# ATSAMRH707F18A register map
Vendor: Microchip Technology; Series: SAMRH707; File version: 0
CPU: CM7 r1p1, little endian, MPU, FPU, double-precision FPU, I-cache, D-cache, ITCM, DTCM, 3 interrupt priority bits, 69 interrupts
Registers are 32-bit, read-write, reset 0x0 unless marked. A register's access mark holds for its fields unless they carry their own. Offsets are from the block's base; [hi:lo] are bit positions; {n}, {i} and the like mark numbered series; 'fields as' and 'values as' point back to an identical list.

## PMC — Power Management Controller
Base 0x4000C000
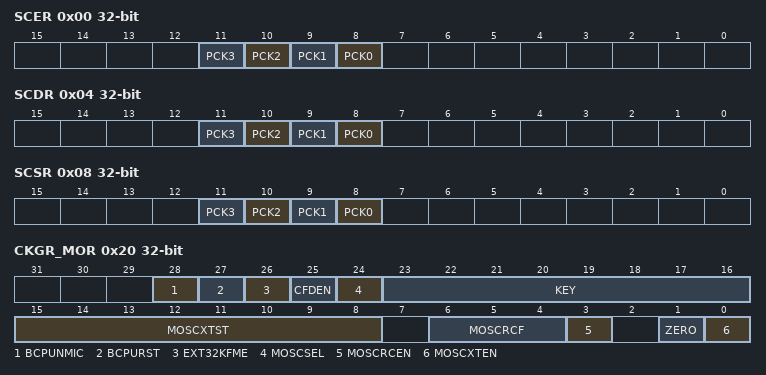
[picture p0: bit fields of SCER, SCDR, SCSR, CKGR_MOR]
0x00 SCER wo — System Clock Enable Register
  [n+8] PCK{n} (n=0..3) — Programmable Clock {n} Output Enable
0x04 SCDR wo — System Clock Disable Register
  [n+8] PCK{n} (n=0..3) — Programmable Clock {n} Output Disable
0x08 SCSR ro — System Clock Status Register
  [n+8] PCK{n} (n=0..3) — Programmable Clock {n} Output Status
0x20 CKGR_MOR — Main Oscillator Register
  [28] BCPUNMIC — Bad CPU Clock Interrupt to NMIC Enable
  [27] BCPURST — Bad CPU Clock Reset Enable
  [26] EXT32KFME — 32.768 kHz External Slow clock Frequency Monitoring Enable
  [25] CFDEN — Clock Failure Detector Enable
  [24] MOSCSEL — Main Clock Oscillator Selection
  [23:16] KEY — Write Access Password
    55=PASSWD (Writing any other value in this field aborts the write operation. Always reads as 0.)
  [15:8] MOSCXTST — Main Crystal Oscillator Startup Time
  [6:4] MOSCRCF — Main RC Oscillator Frequency Selection
    0=_4_MHz (The RC oscillator frequency is at 4 MHz); 1=_8_MHz (The RC oscillator frequency is at 8 MHz); 2=_10_MHz (The RC oscillator frequency is at 10 MHz); 3=_12_MHz (The RC oscillator frequency is at 12 MHz)
  [3] MOSCRCEN — Main RC Oscillator Enable
  [1] ZERO — Shall be always write at '0'
  [0] MOSCXTEN — Main Crystal Oscillator Enable
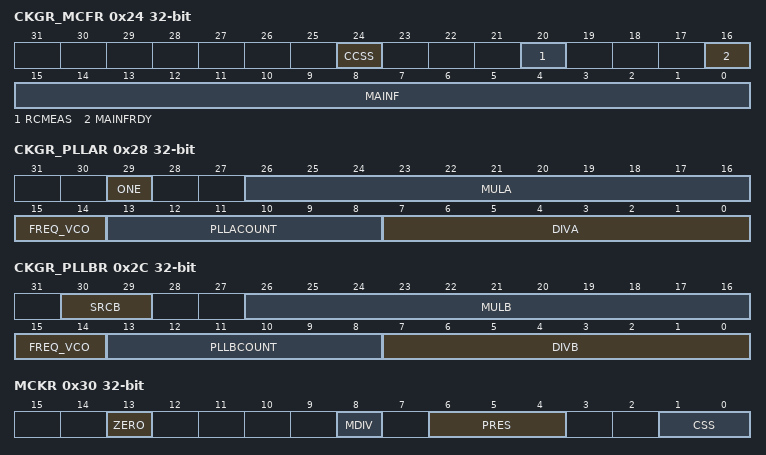
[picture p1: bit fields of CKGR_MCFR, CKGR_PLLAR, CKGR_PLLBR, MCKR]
0x24 CKGR_MCFR — Main Clock Frequency Register
  [24] CCSS — Counter Clock Source Selection
  [20] RCMEAS — RC Oscillator Frequency Measure (write-only)
  [16] MAINFRDY — Main Clock Frequency Measure Ready
  [15:0] MAINF — Main Clock Frequency
0x28 CKGR_PLLAR — PLLA Register
  [29] ONE — Must Be Set to 1
  [26:16] MULA — PLLA Multiplier
  [15:14] FREQ_VCO — VCO Frequency Configuratio
    0=VCO0 (Frequency range: 40-80 MHz); 1=VCO1 (Frequency range: 70-150 MHz); 2=VCO2 (Frequency range: 125-275 MHz); 3=VCO3 (Frequency range: 250-450 MHz)
  [13:8] PLLACOUNT — PLLA Counter
  [7:0] DIVA — PLLA Front End Divider
    0=PLLA is disabled; 1=BYPASS (Divider is bypassed (divide by 1) and PLLA is enabled.)
0x2C CKGR_PLLBR — PLLB Register
  [30:29] SRCB — PLLB Source Clock Selection
    0=MAINCK (MAINCK is the source clock of PLLB.); 2=RC2CK (RC2CK is the source clock of PLLB.)
  [26:16] MULB — PLLB Multiplier
  [15:14] FREQ_VCO — VCO Frequency Configuration
    values as CKGR_PLLAR.FREQ_VCO
  [13:8] PLLBCOUNT — PLLB Counter
  [7:0] DIVB — PLLB Front End Divider
    0=PLLBis disabled; 1=BYPASS (Divider is bypassed (divide by 1) and PLLB is enabled.)
0x30 MCKR — Master Clock Register
  [13] ZERO — Shall be always write at '0'
  [8] MDIV — Master Clock Division
    0=EQ_PCK (MCK is FCLK divided by 1.); 1=PCK_DIV2 (MCK is FCLK divided by 2.)
  [6:4] PRES — Processor Clock Prescaler
    0=CLK_1 (Selected clock); 1=CLK_2 (Selected clock divided by 2); 2=CLK_4 (Selected clock divided by 4); 3=CLK_8 (Selected clock divided by 8); 4=CLK_16 (Selected clock divided by 16); 5=CLK_32 (Selected clock divided by 32); 6=CLK_64 (Selected clock divided by 64)
  [1:0] CSS — Master Clock Source Selection
    0=SLOW_CLK (MD_SLCK is selected); 1=MAIN_CLK (MAINCK is selected); 2=PLLA_CLK (PLLACK is selected)
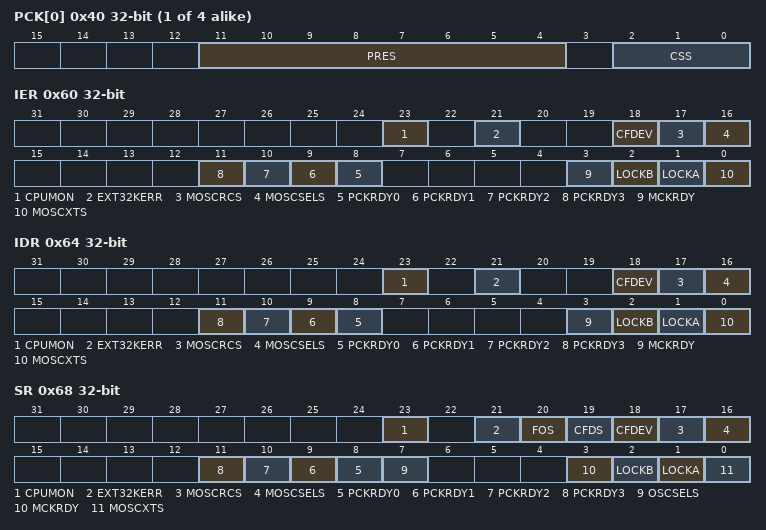
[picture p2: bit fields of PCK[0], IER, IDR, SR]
{0x40+4i} PCK[{i}] (i=0..3) — Programmable Clock Register
  [11:4] PRES — Programmable Clock Prescaler
  [2:0] CSS — Programmable Clock Source Selection
    0=SLOW_CLK (MD_SLCK is selected); 1=MAIN_CLK (MAINCK is selected); 2=PLLA_CLK (PLLACK is selected); 3=PLLB_CLK (PLLBCKDIV is selected); 4=MCK (MCK is selected)
0x60 IER wo — Interrupt Enable Register
  [23] CPUMON — CPU Clock Monitor Interrupt Enable
  [21] EXT32KERR — 32.768 kHz external slow clock Error Interrupt Enable
  [18] CFDEV — Clock Failure Detector Event Interrupt Enable
  [17] MOSCRCS — Main RC Oscillator Status Interrupt Enable
  [16] MOSCSELS — Main Clock Source Oscillator Selection Status Interrupt Enable
  [n+8] PCKRDY{n} (n=0..3) — Programmable Clock Ready {n} Interrupt Enable
  [3] MCKRDY — Master Clock Ready Interrupt Enable
  [2] LOCKB — PLLB Lock Interrupt Enable
  [1] LOCKA — PLLA Lock Interrupt Enable
  [0] MOSCXTS — Main Crystal Oscillator Status Interrupt Enable
0x64 IDR wo — Interrupt Disable Register
  [23] CPUMON — CPU Clock Monitor Interrupt Disable
  [21] EXT32KERR — 32.768 kHz external slow clock Error Interrupt Disable
  [18] CFDEV — Clock Failure Detector Event Interrupt Disable
  [17] MOSCRCS — Main RC Status Interrupt Disable
  [16] MOSCSELS — Main Clock Source Oscillator Selection Status Interrupt Disable
  [n+8] PCKRDY{n} (n=0..3) — Programmable Clock Ready {n} Interrupt Disable
  [3] MCKRDY — Master Clock Ready Interrupt Disable
  [2] LOCKB — PLLB Lock Interrupt Disable
  [1] LOCKA — PLLA Lock Interrupt Disable
  [0] MOSCXTS — Main Crystal Oscillator Status Interrupt Disable
0x68 SR ro — Status Register
  [23] CPUMON — CPU Clock Monitor Error
  [21] EXT32KERR — External Slow Clock Error
  [20] FOS — Clock Failure Detector Fault Output Status
  [19] CFDS — Clock Failure Detector Status
  [18] CFDEV — Clock Failure Detector Event
  [17] MOSCRCS — Main RC Oscillator Status
  [16] MOSCSELS — Main Clock Source Oscillator Selection Status
  [n+8] PCKRDY{n} (n=0..3) — Programmable Clock Ready Status
  [7] OSCSELS — Monitoring Domain Slow Clock Source Oscillator Selection
  [3] MCKRDY — Master Clock Status
  [2] LOCKB — PLLB Lock Status
  [1] LOCKA — PLLA Lock Status
  [0] MOSCXTS — Main Crystal Oscillator Status
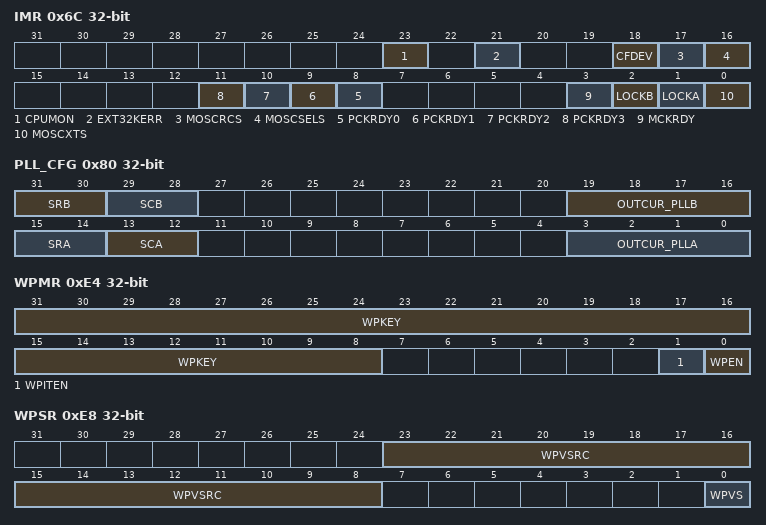
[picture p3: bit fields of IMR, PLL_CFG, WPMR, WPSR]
0x6C IMR ro — Interrupt Mask Register
  [23] CPUMON — CPU Clock Monitor Error Interrupt Mask
  [21] EXT32KERR — 32.768 kHz Slow Clock Error Interrupt Mask
  [18] CFDEV — Clock Failure Detector Event Interrupt Mask
  [17] MOSCRCS — Main RC Status Interrupt Mask
  [16] MOSCSELS — Main Clock Source Oscillator Selection Status Interrupt Mask
  [n+8] PCKRDY{n} (n=0..3) — Programmable Clock Ready {n} Interrupt Mask
  [3] MCKRDY — Master Clock Ready Interrupt Mask
  [2] LOCKB — PLLB Lock Interrupt Mask
  [1] LOCKA — PLLA Lock Interrupt Mask
  [0] MOSCXTS — Main Crystal Oscillator Status Interrupt Mask
0x78 FOCR wo — Fault Output Clear Register
  [0] FOCLR — Fault Output Clear
0x80 PLL_CFG — PLL Configuration Register
  [31:30] SRB — Internal Filter PLL - Select Internal Resistor Value
    0=SR_VAL_24K (24 Ohms); 1=SR_VAL_6K (6 Ohms); 2=SR_VAL_3K (3 Ohms); 3=SR_VAL_12K (12 Ohms)
  [29:28] SCB — Internal Filter PLL - Select Internal Capaticance Value
    0=SC_VAL_20p (20 pF); 1=SC_VAL_40p (40 pF); 2=SC_VAL_30p (30 pF); 3=SC_VAL_60p (60 pF)
  [19:16] OUTCUR_PLLB — PLLB Output Current
    0=ICP0 (0.5 mA); 1=ICP1 (0.75 mA); 2=ICP2 (1 mA); 3=ICP3 (1.25 mA)
  [15:14] SRA — Internal Filter PLL - Select Internal Resistor Value
    values as SRB
  [13:12] SCA — Internal Filter PLL - Select Internal Capaticance Value
    values as SCB
  [3:0] OUTCUR_PLLA — PLLA Output Current
    values as OUTCUR_PLLB
0xE4 WPMR — Write Protection Mode Register
  [31:8] WPKEY — Write Protection Key
    0x504D43=PASSWD (Writing any other value in this field aborts the write operation of the WPEN bit. Always reads as 0.)
  [1] WPITEN — Write Protection Interrupt Enable
  [0] WPEN — Write Protection Enable
0xE8 WPSR ro — Write Protection Status Register
  [23:8] WPVSRC — Write Protection Violation Source
  [0] WPVS — Write Protection Violation Status
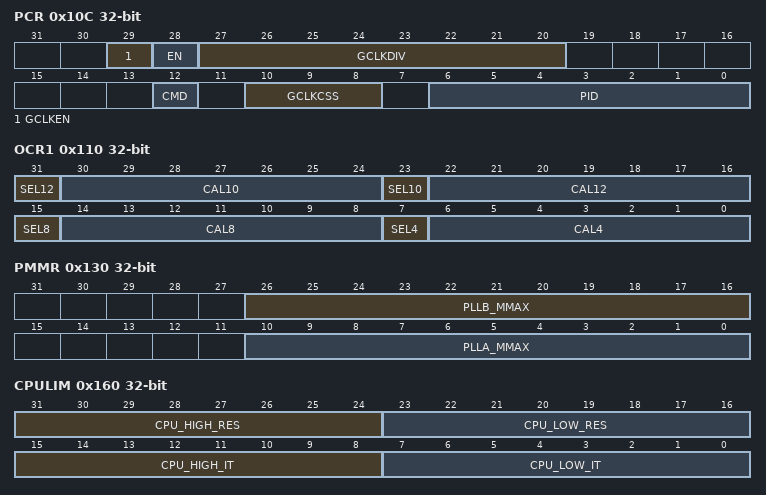
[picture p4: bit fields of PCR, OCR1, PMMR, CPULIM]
0x10C PCR — Peripheral Control Register
  [29] GCLKEN — Generic Clock Enable
  [28] EN — Enable
  [27:20] GCLKDIV — Generic Clock Division Ratio
  [12] CMD — Command
  [10:8] GCLKCSS — Generic Clock Source Selection
    0=SLOW_CLK (MD_SLCK is selected); 1=MAIN_CLK (MAINCK is selected); 2=PLLA_CLK (PLLACK is selected); 3=PLLB_CLK (PLLBCK is selected); 4=MCK_CLK (MCK is selected); 5=MCK_RC2 (RC2 is selected)
  [6:0] PID — Peripheral ID
0x110 OCR1 — Oscillator Calibration Register
  [31] SEL12 — Selection of Main RC Oscillator Calibration Bits for 12 MHz
  [30:24] CAL10 — Main RC Oscillator Calibration Bits for 10 MHz
  [23] SEL10 — Selection of Main RC Oscillator Calibration Bits for 10 MHz
  [22:16] CAL12 — Main RC Oscillator Calibration Bits for 12 MHz
  [15] SEL8 — Selection of Main RC Oscillator Calibration Bits for 8 MHz
  [14:8] CAL8 — Main RC Oscillator Calibration Bits for 8 MHz
  [7] SEL4 — Selection of Main RC Oscillator Calibration Bits for 4 MHz
  [6:0] CAL4 — Main RC Oscillator Calibration Bits for 4 MHz
0x130 PMMR — PLL Maximum Multiplier Value Register
  [26:16] PLLB_MMAX — PLLB Maximum Allowed Multiplier Value
  [10:0] PLLA_MMAX — PLLA Maximum Allowed Multiplier Value
0x160 CPULIM — CPU Monitor Limits Register
  [31:24] CPU_HIGH_RES — CPU Monitoring High Reset Limit
  [23:16] CPU_LOW_RES — CPU Monitoring Low RESET Limit
  [15:8] CPU_HIGH_IT — CPU Monitoring High IT Limit
  [7:0] CPU_LOW_IT — CPU Monitoring Low IT Limit
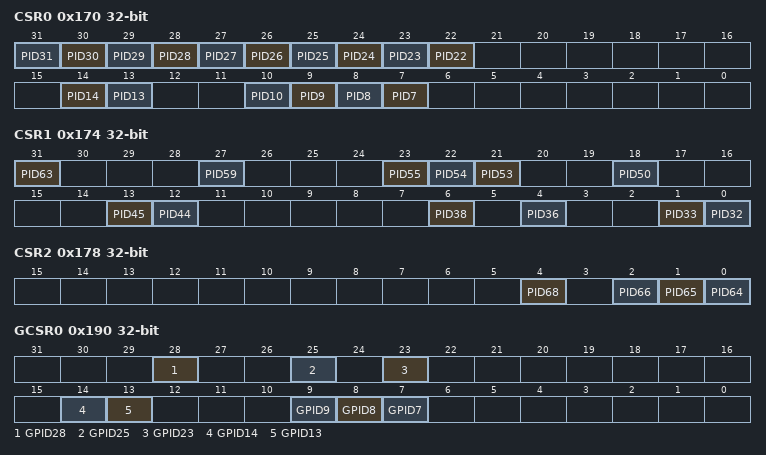
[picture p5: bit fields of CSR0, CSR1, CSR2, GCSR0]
0x170 CSR0 ro — Peripheral Clock Status Register 0
  [n] PID{n} (n=22..31) — Peripheral Clock {n} Status
  [14] PID14 — Peripheral Clock 14 Status
  [13] PID13 — Peripheral Clock 13 Status
  [n] PID{n} (n=7..10) — Peripheral Clock {n} Status
0x174 CSR1 ro — Peripheral Clock Status Register 1
  [31] PID63 — Peripheral Clock 63 Status
  [27] PID59 — Peripheral Clock 59 Status
  [23] PID55 — Peripheral Clock 55 Status
  [22] PID54 — Peripheral Clock 54 Status
  [21] PID53 — Peripheral Clock 53 Status
  [18] PID50 — Peripheral Clock 50 Status
  [13] PID45 — Peripheral Clock 45 Status
  [12] PID44 — Peripheral Clock 44 Status
  [6] PID38 — Peripheral Clock 38 Status
  [4] PID36 — Peripheral Clock 36 Status
  [1] PID33 — Peripheral Clock 33 Status
  [0] PID32 — Peripheral Clock 32 Status
0x178 CSR2 ro — Peripheral Clock Status Register 2
  [4] PID68 — Peripheral Clock 68 Status
  [2] PID66 — Peripheral Clock 66 Status
  [1] PID65 — Peripheral Clock 65 Status
  [0] PID64 — Peripheral Clock 64 Status
0x17C CSR3 ro — Peripheral Clock Status Register 3
0x190 GCSR0 ro — Generic Clock Status Register 0
  [28] GPID28 — Generic Clock 28 Status
  [25] GPID25 — Generic Clock 25 Status
  [23] GPID23 — Generic Clock 23 Status
  [14] GPID14 — Generic Clock 14 Status
  [13] GPID13 — Generic Clock 13 Status
  [9] GPID9 — Generic Clock 9 Status
  [8] GPID8 — Generic Clock 8 Status
  [7] GPID7 — Generic Clock 7 Status
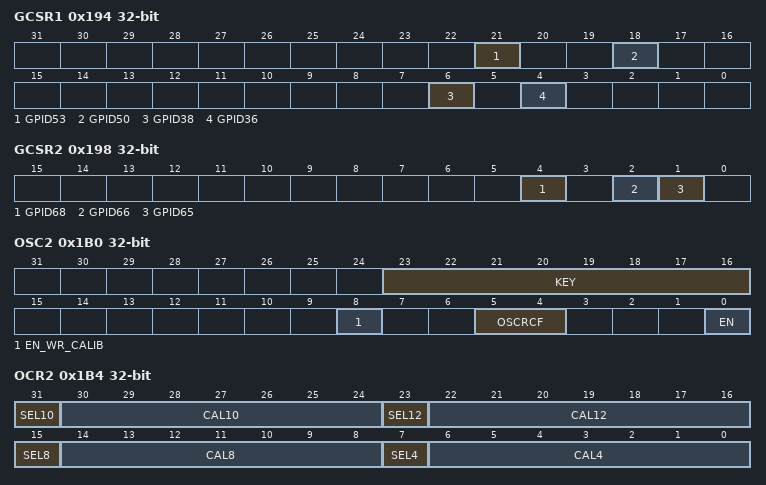
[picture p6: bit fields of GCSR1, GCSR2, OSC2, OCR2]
0x194 GCSR1 ro — Generic Clock Status Register 1
  [21] GPID53 — Generic Clock 53 Status
  [18] GPID50 — Generic Clock 50 Status
  [6] GPID38 — Generic Clock 38 Status
  [4] GPID36 — Generic Clock 36 Status
0x198 GCSR2 ro — Generic Clock Status Register 2
  [4] GPID68 — Generic Clock 68 Status
  [2] GPID66 — Generic Clock 66 Status
  [1] GPID65 — Generic Clock 65 Status
0x19C GCSR3 ro — Generic Clock Status Register 3
0x1B0 OSC2 — Oscillator Control Register 2
  [23:16] KEY — Register Write Access Password
    55=PASSWD (Writing any other value in this field aborts the write operation.Always reads as 0.)
  [8] EN_WR_CALIB — Enable Calibration Register Write
  [5:4] OSCRCF — 2nd Oscillator Frequency Selection
    0=_4_MHz (The 2nd RC oscillator frequency is at 4 MHz); 1=_8_MHz (The 2nd RC oscillator frequency is at 8 MHz); 2=_10_MHz (The 2nd RC oscillator frequency is at 10 MHz); 3=_12_MHz (The 2nd RC oscillator frequency is at 12 MHz)
  [0] EN — Enable
0x1B4 OCR2 — Oscillator Calibration Register 2
  [31] SEL10 — Selection of Main RC Oscillator Calibration Bits for 10 MHz
  [30:24] CAL10 — Main RC Oscillator Calibration Bits for 10 MHz
  [23] SEL12 — Selection of Main RC Oscillator Calibration Bits for 12 MHz
  [22:16] CAL12 — Main RC Oscillator Calibration Bits for 12 MHz
  [15] SEL8 — Selection of Main RC Oscillator Calibration Bits for 8 MHz
  [14:8] CAL8 — Main RC Oscillator Calibration Bits for 8 MHz
  [7] SEL4 — Selection of Main RC Oscillator Calibration Bits for 4 MHz
  [6:0] CAL4 — Main RC Oscillator Calibration Bits for 4 MHz
